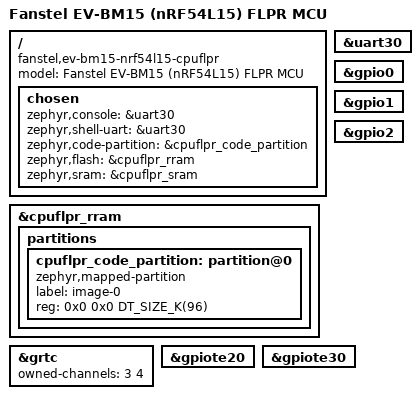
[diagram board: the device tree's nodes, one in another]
/*
 * Copyright (c) 2024 Nordic Semiconductor ASA
 *
 * SPDX-License-Identifier: Apache-2.0
 */

/dts-v1/;
#include <nordic/nrf54l15_cpuflpr.dtsi>
#include "fanstel_ev_bm15_cpuflpr_common.dtsi"

/ {
	model = "Fanstel EV-BM15 (nRF54L15) FLPR MCU";
	compatible = "fanstel,ev-bm15-nrf54l15-cpuflpr";

	chosen {
		zephyr,console = &uart30;
		zephyr,shell-uart = &uart30;
		zephyr,code-partition = &cpuflpr_code_partition;
		zephyr,flash = &cpuflpr_rram;
		zephyr,sram = &cpuflpr_sram;
	};
};

&cpuflpr_rram {
	partitions {
		ranges;

		cpuflpr_code_partition: partition@0 {
			compatible = "zephyr,mapped-partition";
			label = "image-0";
			reg = <0x0 0x0 DT_SIZE_K(96)>;
		};
	};
};

&grtc {
	owned-channels = <3 4>;
	status = "okay";
};

&uart30 {
	status = "okay";
};

&gpio0 {
	status = "okay";
};

&gpio1 {
	status = "okay";
};

&gpio2 {
	status = "okay";
};

&gpiote20 {
	status = "okay";
};

&gpiote30 {
	status = "okay";
};
